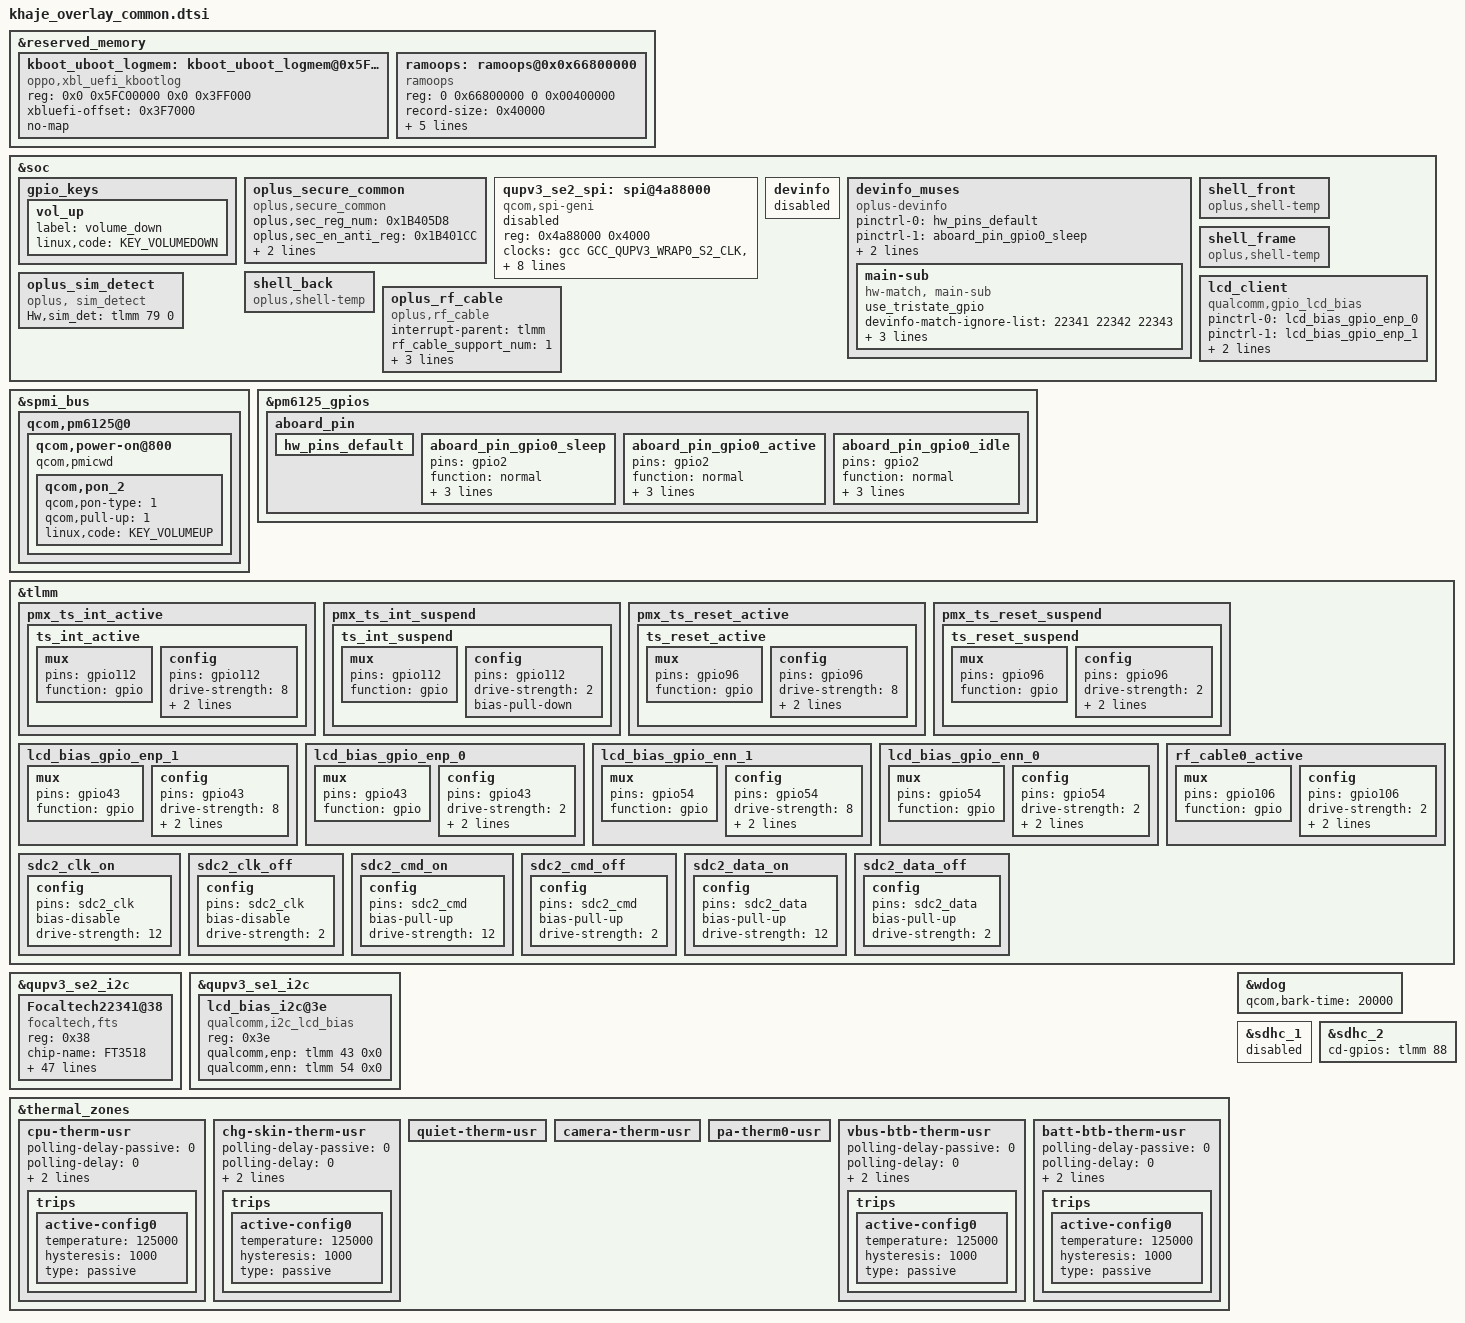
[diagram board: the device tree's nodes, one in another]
//#include "sensor/muses-sensor-mtp.dtsi"
// xbl_uefi_mem address get from boot_images Core.dsc.inc file: PcdEmbeddedFdBaseAddress + SERIAL_BUFFER_OFFSET,0x5FC00000+0x3F7000
// kernel boot log: 0x5FC00000~ 0x5FFF7000
&reserved_memory {
        kboot_uboot_logmem: kboot_uboot_logmem@0x5FC00000 {
                reg = <0x0 0x5FC00000 0x0 0x3FF000>;
                compatible = "oppo,xbl_uefi_kbootlog";
                xbluefi-offset = <0x3F7000>;
                no-map;
        };

        ramoops: ramoops@0x0x66800000 {
                compatible = "ramoops";
                reg = <0 0x66800000 0 0x00400000>;
                record-size =  <0x40000>; //256x1024
                console-size = <0x40000>;
                ftrace-size =  <0x40000>;
                pmsg-size=         <0x200000>;
                devinfo-size=  <0x01000>;
                ecc-size=          <0x0>;
        };
};

#include "fingerprint/khaje-muses-fingerprint-overlay.dtsi"

&soc {
	gpio_keys {
		vol_up {
			/delete-property/ label;
			label = "volume_down";
			/delete-property/ linux,code;
			linux,code = <KEY_VOLUMEDOWN>;
		};
	};

        // #ifdef OPLUS_FEATURE_SECURITY_COMMON
        oplus_secure_common {
            compatible = "oplus,secure_common";
            oplus,sec_reg_num = <0x1B405D8>;
            oplus,sec_en_anti_reg = <0x1B401CC>;
            oplus,sec_override1_reg = <0x7860C0>;
            oplus,override1_en_value = <0x1>;
        };
        //#endif /* OPLUS_FEATURE_SECURITY_COMMON */

	qupv3_se2_spi: spi@4a88000 {
		compatible = "qcom,spi-geni";
		#address-cells = <1>;
		#size-cells = <0>;
		reg = <0x4a88000 0x4000>;
		reg-names = "se_phys";
		clock-names = "se-clk", "m-ahb", "s-ahb";
		clocks = <&gcc GCC_QUPV3_WRAP0_S2_CLK>,
		<&gcc GCC_QUPV3_WRAP_0_M_AHB_CLK>,
		<&gcc GCC_QUPV3_WRAP_0_S_AHB_CLK>;
		pinctrl-names = "default", "sleep";
		pinctrl-0 = <>;
		pinctrl-1 = <>;

		interrupts = <GIC_SPI 329 IRQ_TYPE_LEVEL_HIGH>;
		spi-max-frequency = <50000000>;
		qcom,wrapper-core = <&qupv3_0>;
		dmas = <&gpi_dma0 0 2 1 64 0>,
		<&gpi_dma0 1 2 1 64 0>;
		dma-names = "tx", "rx";
		status = "disabled";
	};
        devinfo {
                status = "disabled";
        };
        devinfo_muses {
                compatible = "oplus-devinfo";

                pinctrl-names = "default", "sleep", "active", "idle";
                pinctrl-0 = <&hw_pins_default>;
                pinctrl-1 = <&aboard_pin_gpio0_sleep>;
                pinctrl-2 = <&aboard_pin_gpio0_active>;
                pinctrl-3 = <&aboard_pin_gpio0_idle>;
                main-sub {
                        use_tristate_gpio;
			devinfo-match-ignore-list = <22341 22342 22343>;
                        compatible = "hw-match, main-sub";
                        aboard-gpio0 = <&pm6125_gpios 2 0>;
                        aboard-patterns = <0 1 0>;    /*0[high-resistance] 1[pull-down] 2[pull-up]*/
                        /*main board*/
                        match-projects = <22341 22342 22343>;
                };
        };
        //#ifdef OPLUS_FEATURE_THERMAL_HORAE
        shell_front {
            compatible = "oplus,shell-temp";
        };

        shell_frame {
            compatible = "oplus,shell-temp";
        };

        shell_back {
            compatible = "oplus,shell-temp";
        };
        //#endif /* OPLUS_FEATURE_THERMAL_HORAE */
		lcd_client {
			compatible = "qualcomm,gpio_lcd_bias";
			pinctrl-names = "lcd_bias_gpio_enp0","lcd_bias_gpio_enp1","lcd_bias_gpio_enn0","lcd_bias_gpio_enn1";
			pinctrl-0 = <&lcd_bias_gpio_enp_0>;
			pinctrl-1 = <&lcd_bias_gpio_enp_1>;
			pinctrl-2 = <&lcd_bias_gpio_enn_0>;
			pinctrl-3 = <&lcd_bias_gpio_enn_1>;
			status = "okay";
		};
        //#ifdef OPLUS_FEATURE_TP_BASIC
		oplus_sim_detect {
			compatible = "oplus, sim_detect";
			Hw,sim_det = <&tlmm 79 0>;
		};
        //#endif /* OPLUS_FEATURE_TP_BASIC */

	oplus_rf_cable {
		compatible = "oplus,rf_cable";
		interrupt-parent = <&tlmm>;
		rf_cable_support_num = <1>;
		rf,cable0-gpio = <&tlmm 106 0>;
		rf,cable-support-timer = <0>;
		pinctrl-names = "rf_cable_active";
		pinctrl-0 = <&rf_cable0_active>;
	};
};

&spmi_bus {
	qcom,pm6125@0 {
		qcom,power-on@800 {
			qcom,pmicwd;
			qcom,pon_2 {
				qcom,pon-type = <1>;
				qcom,pull-up = <1>;
				linux,code = <KEY_VOLUMEUP>;
			};
		};
    };
};
&pm6125_gpios {
        aboard_pin {
                hw_pins_default:hw_pins_default {
                };

                aboard_pin_gpio0_sleep:aboard_pin_gpio0_sleep {
                pins = "gpio2";
                        function = "normal";
                        bias-pull-down;
                        input-enable;
                        power-source = <0>;
                };

                aboard_pin_gpio0_active:aboard_pin_gpio0_active {
                pins = "gpio2";
                        function = "normal";
                        bias-pull-up;
                        input-enable;
                        power-source = <0>;
                };

                aboard_pin_gpio0_idle:aboard_pin_gpio0_idle {
                pins = "gpio2";
                        function = "normal";
                        bias-disable;
                        input-enable;
                        power-source = <0>;
                };
        };
};

&tlmm {

	pmx_ts_int_active {
		ts_int_active: ts_int_active {
			mux {
				pins = "gpio112";
				function = "gpio";
			};

			config {
				pins = "gpio112";
				drive-strength = <8>;
				bias-pull-up;
				input-enable;
			};
		};
	};

	pmx_ts_int_suspend {
		ts_int_suspend: ts_int_suspend {
			mux {
				pins = "gpio112";
				function = "gpio";
			};

			config {
				pins = "gpio112";
				drive-strength = <2>;
				bias-pull-down;
			};
		};
	};

	pmx_ts_reset_active {
		ts_reset_active: ts_reset_active {
			mux {
				pins = "gpio96";
				function = "gpio";
			};

			config {
				pins = "gpio96";
				drive-strength = <8>;
				output-high;
				bias-pull-up;
			};
		};
	};

	pmx_ts_reset_suspend {
		ts_reset_suspend: ts_reset_suspend {
			mux {
				pins = "gpio96";
				function = "gpio";
			};

			config {
				pins = "gpio96";
				drive-strength = <2>;
				output-low;
				bias-pull-down;
			};
		};
	};
	lcd_bias_gpio_enp_1: lcd_bias_gpio_enp_1 {
		mux {
			pins = "gpio43";
			function = "gpio";
		};

		config {
			pins = "gpio43";
			drive-strength = <8>;
			output-high;
			bias-pull-up;
		};
	};

	lcd_bias_gpio_enp_0: lcd_bias_gpio_enp_0 {
		mux {
			pins = "gpio43";
			function = "gpio";
		};

		config {
			pins = "gpio43";
			drive-strength = <2>;
			output-low;
			bias-pull-down;
		};
	};

	lcd_bias_gpio_enn_1: lcd_bias_gpio_enn_1 {
		mux {
			pins = "gpio54";
			function = "gpio";
		};

		config {
			pins = "gpio54";
			drive-strength = <8>;
			output-high;
			bias-pull-up;
		};
	};

	lcd_bias_gpio_enn_0: lcd_bias_gpio_enn_0 {
		mux {
			pins = "gpio54";
			function = "gpio";
		};

		config {
			pins = "gpio54";
			drive-strength = <2>;
			output-low;
			bias-pull-down;
		};
	};

	rf_cable0_active: rf_cable0_active {
		mux {
			pins = "gpio106";
			function = "gpio";
		};
		config {
			pins = "gpio106";
			drive-strength = <2>;
			input-enable;
			bias-pull-up;
		};
	};
	sdc2_clk_on: sdc2_clk_on {
		config {
			pins = "sdc2_clk";
			bias-disable;		/* NO pull */
			drive-strength = <12>;	/* 12 MA */
		};
	};

	sdc2_clk_off: sdc2_clk_off {
		config {
			pins = "sdc2_clk";
			bias-disable;		/* NO pull */
			drive-strength = <2>;	/* 2 MA */
		};
	};

	sdc2_cmd_on: sdc2_cmd_on {
		config {
			pins = "sdc2_cmd";
			bias-pull-up;		/* pull up */
			drive-strength = <12>;	/* 12 MA */
		};
	};

	sdc2_cmd_off: sdc2_cmd_off {
		config {
			pins = "sdc2_cmd";
			bias-pull-up;		/* pull up */
			drive-strength = <2>;	/* 2 MA */
		};
	};

	sdc2_data_on: sdc2_data_on {
		config {
			pins = "sdc2_data";
			bias-pull-up;		/* pull up */
			drive-strength = <12>;	/* 12 MA */
		};
	};

	sdc2_data_off: sdc2_data_off {
		config {
			pins = "sdc2_data";
			bias-pull-up;		/* pull up */
			drive-strength = <2>;	/* 2 MA */
		};
	};

};

&qupv3_se2_i2c {
	#address-cells = <1>;
	#size-cells = <0>;

	status = "ok";

	Focaltech22341@38 {
		compatible = "focaltech,fts";
		reg = <0x38>;
		chip-name = "FT3518";

		/* Interrupt && Irq-gpio */
		interrupt-parent = <&tlmm>;
		interrupts = <112 0x2002>;

		/* Power Config */
		enable2v8_gpio = <&tlmm 54 0x1>;
		//vdd_2v8_volt = <3008000>;

		/* Other HW Resource */
		irq-gpio = <&tlmm 112 0x2002>;
		reset-gpio = <&tlmm 96 0x1>;
		pinctrl-names = "default";
		pinctrl-0 = <&ts_int_active &ts_reset_active>;

		//vid_len = <2>;
		project_id = <22341>;
		// type of tp_dev ,TP-SAMSUNG = 8;
		panel_type = <8>;
		tp_type = <8>;
		//firmware_name = "0xAA31100";
		platform_support_project = <22341 22342 22343>;
		platform_support_project_dir = <22341 22341 22341>;
		platform_support_project_commandline = "default_commandline","default_commandline","default_commandline";
		//platform_support_project_external_name = "AA311", "AA311", "AA311", "AA311", "AA311";

		touchpanel,max-num-support = <10>;
		touchpanel,tx-rx-num = <16 34>;
		touchpanel,panel-coords = <4320 9600>;
		touchpanel,display-coords = <1080 2400>;
		touchpanel,touchmajor-limit = <0 54>;
		touchpanel,report-rate = <120 180>;
		touchpanel,smooth-level = <255 2 15 25 45 60>;
		touchpanel,smooth-level-charging = <255 15 20 25 45 60>;
		touchpanel,sensitive-level = <255 20 16 13 10 5>;
		touchpanel,single-optimized-time = <8>;
		touchpanel,game_perf_para_default = <25 7>;
		touchpanel,msecs-to-jiffies-time = <100>;

		//prevention,dead_area_width = <20 20>;
		//prevention,condition_area_width = <60 60 160 160>;
		//prevention,eli_area_width = <240 1000 1200 240>;

		/* SW Support Feature Control */
		black_gesture_support;
		black_gesture_indep_support;
		/* sportify_aod_gesture_support; */
		fw_edge_limit_support;
		pressure_report_support;
		charger_pump_support;
		game_switch_support;
		smart_gesture_support;
		fw_update_app_support;
		fingerprint_underscreen_support;
		headset_pump_support;
		irq_need_dev_resume_ok;
		health_monitor_v2_support;
		high_resolution_support;
		esd_handle_support;
		lcd_tp_refresh_support;
		disable_suspend_irq_handler_support;
		exception_upload_support;
		/*
		 *Virtual Key Config:
		 *1:touchpanel,button-type: <virtualkey_type  supportted_button-map>
		 *virtualkey_type:
		 *Type 1: using board_properties
		 *Type 2: using same IC (button zone&& touch zone are seprate)
		 *Type 3: using diffrent IC (button zone&& touch zone are seprate)
		 *Type 4: No need of virtual key process
		 *supportted_button-map:select|menu|home|back
		 *
		 *2:touchpanel,button-map
		 *type (X1,Y1)(X2,Y2)(X3,Y3)(Width_X,Hight_Y)--Only when button-type is 0
		 */
		touchpanel,button-type = <4>;
		touchpanel.button-TRx = <0 0>;
	};
};

&qupv3_se1_i2c {
	lcd_bias_i2c@3e {
		compatible = "qualcomm,i2c_lcd_bias";
		reg = <0x3e>;
		qualcomm,enp = <&tlmm 43 0x0>;
		qualcomm,enn = <&tlmm 54 0x0>;
		status = "okay";
	};
};
//#ifdef OPLUS_TEMP_NTC
&thermal_zones {
        cpu-therm-usr {
                polling-delay-passive = <0>;
                polling-delay = <0>;
                thermal-governor = "user_space";
                wake-capable-sensor;
                trips {
                        active-config0 {
                                temperature = <125000>;
                                hysteresis = <1000>;
                                type = "passive";
                        };
                };
        };

        chg-skin-therm-usr {
                polling-delay-passive = <0>;
                polling-delay = <0>;
                thermal-governor = "user_space";
                wake-capable-sensor;
                trips {
                        active-config0 {
                                temperature = <125000>;
                                hysteresis = <1000>;
                                type = "passive";
                        };
                };
        };

        quiet-therm-usr {
                /delete-property/ thermal-sensors;
        };

        camera-therm-usr {
                /delete-property/ thermal-sensors;
        };

        pa-therm0-usr {
                /delete-property/ thermal-sensors;
        };

        vbus-btb-therm-usr {
                polling-delay-passive = <0>;
                polling-delay = <0>;
                thermal-governor = "user_space";
                wake-capable-sensor;
                trips {
                        active-config0 {
                                temperature = <125000>;
                                hysteresis = <1000>;
                                type = "passive";
                        };
                };
        };

        batt-btb-therm-usr {
                polling-delay-passive = <0>;
                polling-delay = <0>;
                thermal-governor = "user_space";
                wake-capable-sensor;
                trips {
                        active-config0 {
                                temperature = <125000>;
                                hysteresis = <1000>;
                                type = "passive";
                        };
                };
        };
};
//#endif

//modify bark time to 20s
&wdog {
	/delete-property/ qcom,bark-time;
	qcom,bark-time = <20000>;
};

/* #ifdef OPLUS_FEATURE_EMMC_DRIVER */
&sdhc_1 {
	status = "disabled";
};

&sdhc_2 {
	cd-gpios = <&tlmm 88 GPIO_ACTIVE_HIGH>;
	status = "ok";
};
/* #endif */
